# RL6842_IP_SVD register map
Vendor: Realtek
Registers are 32-bit, read-write, reset 0x0 unless marked. A register's access mark holds for its fields unless they carry their own. Offsets are from the block's base; [hi:lo] are bit positions; {n}, {i} and the like mark numbered series.

## page1 (part 1 of 2)
Base 0x40000000
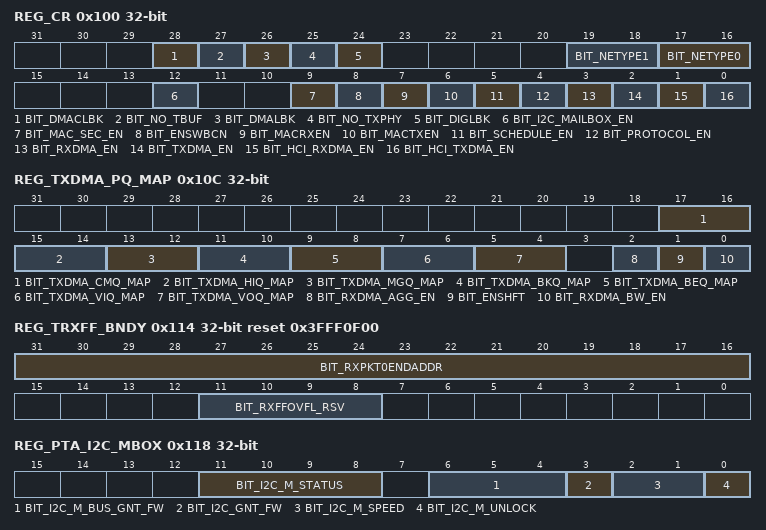
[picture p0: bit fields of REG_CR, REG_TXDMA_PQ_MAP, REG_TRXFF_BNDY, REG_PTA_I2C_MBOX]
0x100 REG_CR — MAC TOP Function enable
  [28] BIT_DMACLBK — [28:24] LBMODE [4]dual-mac lbk, [3] no buffer, 1: no delay, 0: delay; [2] dmalbk, [1] no_txphy, [0] diglbk. 00000: Normal 01011: Single MAC Direct loopback (no HW encryption/decryption) 00011: Single MAC Delay Loopback (with HW encryption/decryption)
  [27] BIT_NO_TBUF
  [26] BIT_DMALBK
  [25] BIT_NO_TXPHY
  [24] BIT_DIGLBK
  [19:18] BIT_NETYPE1 — Network Type for Port 1 00: No link 01: Link in ad hoc network 10: Link in infrastructure network 11 : AP mode Default: 00b.
  [17:16] BIT_NETYPE0 — Network Type for port 0 00: No link 01: Link in ad hoc network 10: Link in infrastructure network 11 : AP mode Default: 00b.
  [12] BIT_I2C_MAILBOX_EN — Enable I2C mailbox
  [9] BIT_MAC_SEC_EN — Enable MAC security engine When this bit is clear, security engine is reset
  [8] BIT_ENSWBCN — Enable SW TX beacon 0 : disable, beacon is DMAed from host memory by HW at BCNDMAINT 1 : enable, beacon is polled to DMA to TXBUF. In both case, as long as a beacon frame is set in BCN page, MAC will automatically sent beacon frame automatically.
  [7] BIT_MACRXEN — MAC Receiver Enable. When set to 1, and the receive state machine is idle, the receive machine becomes active. This bit will read back as 1 whenever the receive state machine is active. After initial power-up, software must ensure that the receiver has completely reset before setting this bit. 1: Enable 0: Disable Default: 0b.
  [6] BIT_MACTXEN — MAC Transmitter Enable. When set to 1, and the transmit state machine is idle, the transmit state machine becomes active. This bit will read back as 1 whenever the transmit state machine is active. After initial power-up, software must ensure that the transmitter has completely reset before setting this bit. 1: Enable 0: Disable Default: 0b.
  [5] BIT_SCHEDULE_EN — Schedule Enable.
  [4] BIT_PROTOCOL_EN — protocol Block Function Enable.(FW2HW)
  [3] BIT_RXDMA_EN — RXDMA Function Enable
  [2] BIT_TXDMA_EN — TXDMA Function Enable
  [1] BIT_HCI_RXDMA_EN — HCI to RXDMA Interface Enable
  [0] BIT_HCI_TXDMA_EN — HCI to TXDMA Interface Enable
0x104 REG_PG_SIZE
0x108 REG_TSF_CLK_STATE ro — Beacon time reset value
  [15] BIT_CLK_TSF_IS32K — Which Clock is Used by TSF Clock 1: 32K Clock 0: MAC Clock
0x10C REG_TXDMA_PQ_MAP — RX DMA Fuction enable
  [17:16] BIT_TXDMA_CMQ_MAP — 00: Extra priority queue 01: Low priority queue 10: Normal priority queue 11: High priority queue
  [15:14] BIT_TXDMA_HIQ_MAP — 00: Extra priority queue 01: Low priority queue 10: Normal priority queue 11: High priority queue
  [13:12] BIT_TXDMA_MGQ_MAP — 00: Extra priority queue 01: Low priority queue 10: Normal priority queue 11: High priority queue
  [11:10] BIT_TXDMA_BKQ_MAP — 00: Extra priority queue 01: Low priority queue 10: Normal priority queue 11: High priority queue
  [9:8] BIT_TXDMA_BEQ_MAP — 00: Extra priority queue 01: Low priority queue 10: Normal priority queue 11: High priority queue
  [7:6] BIT_TXDMA_VIQ_MAP — 00: Extra priority queue 01: Low priority queue 10: Normal priority queue 11: High priority queue
  [5:4] BIT_TXDMA_VOQ_MAP — 00: Extra priority queue 01: Low priority queue 10: Normal priority queue 11: High priority queue
  [2] BIT_RXDMA_AGG_EN — When this bit is set, then RXDMA will inform host to receive RX packets, when packet page number in RXFF exceeds the threshold set in RXDMA_AGG_PG_TH register. When this bit is set, then page size of receive packet buffer shall be set larger than 64 bytes/page
  [1] BIT_ENSHFT — When this bit is set, RX shift to fit alignment is enabled.
  [0] BIT_RXDMA_BW_EN — Enable RXDMA Arbitrator priority for Host interface.
0x114 REG_TRXFF_BNDY reset 0x3FFF0F00 — FIFO Boundary control register
  [31:16] BIT_RXPKT0ENDADDR — This register sets the upper boundary of RXFF0. The unit is 1 byte. The available memory space in RXPKTBUF for RXFF0 is configurable. The value is set to the physical LX bus address.
  [11:8] BIT_RXFFOVFL_RSV — Use this register to set reserved entries number of rxpktbuffer for overflow judgment. The rxpktbuffer overflow will be pre-asserted if the left entries count meets the value set here.
0x118 REG_PTA_I2C_MBOX access per field — Status register-FIFO status
  [11:8] BIT_I2C_M_STATUS ro — Read these can get the I2C_M_STATUS of PTA_I2C's OUTPUT.
  [6:4] BIT_I2C_M_BUS_GNT_FW rw — Use this bit to control PTA_I2C's BUS_GNT. 100 for gnt_txdata, 010 for gnt_txack, 001 for gnt_rxstatus.
  [3] BIT_I2C_GNT_FW rw — Use this bit to control PTA_I2C_GNT_FW input. 1 for FW I2C bus arbiter, 0 for HW as I2C bus arbiter.
  [2:1] BIT_I2C_M_SPEED rw — Use these bit to control PTA_I2C I2C interface data rate. SCL = clk / 2^(3 + I2C_DATA_RATE)
  [0] BIT_I2C_M_UNLOCK rw — If this bit is set, PTA_I2C use 118H and 119H to control PTA_I2C
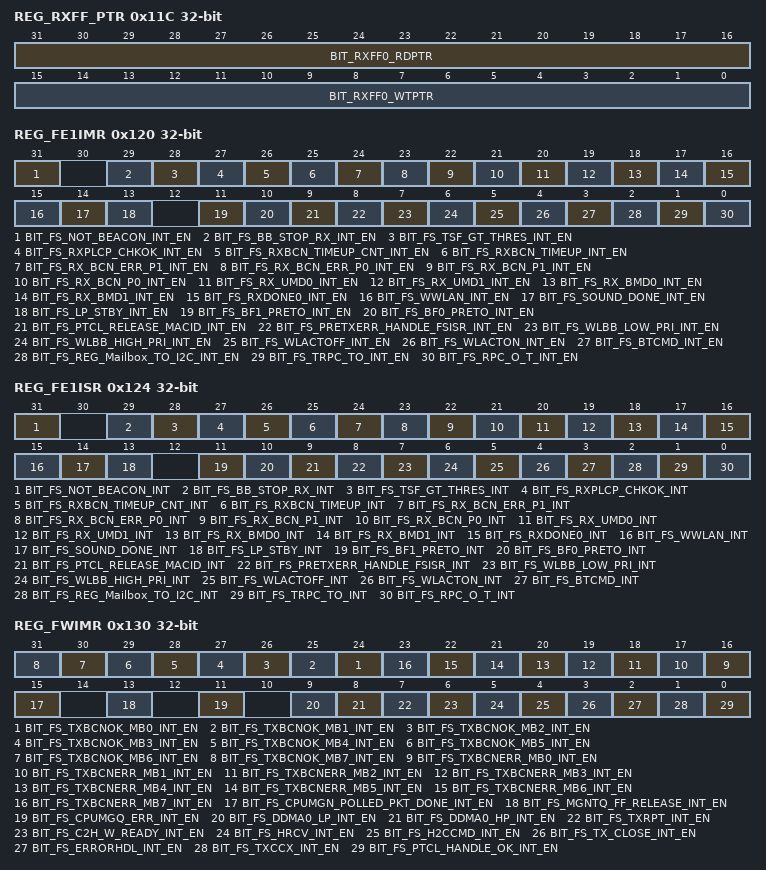
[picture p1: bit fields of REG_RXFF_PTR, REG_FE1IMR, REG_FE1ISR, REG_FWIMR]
0x11C REG_RXFF_PTR ro — RX FIFO Read/write pointer
  [31:16] BIT_RXFF0_RDPTR — The read pointer address of RXFF0. The value is set to the physical LX bus address.
  [15:0] BIT_RXFF0_WTPTR — The write pointer address of RXFF0. The value is set to the physical LX bus address.
0x120 REG_FE1IMR
  [31] BIT_FS_NOT_BEACON_INT_EN — not beacon packet interrupt
  [29] BIT_FS_BB_STOP_RX_INT_EN — BB STOP RX interrupt
  [28] BIT_FS_TSF_GT_THRES_INT_EN — The interrupt is issued when difference of tsft in beacon frame of port0 is greater than threshold
  [27] BIT_FS_RXPLCP_CHKOK_INT_EN — RXPCLP check ok interrupt
  [26] BIT_FS_RXBCN_TIMEUP_CNT_INT_EN — When this bit is enable, the interrupt is issued when RX beacon frame timeout occurs specified times in port0.specified by 0x17C[23:20]
  [25] BIT_FS_RXBCN_TIMEUP_INT_EN — When this bit is enable, the interrupt is issued when RX beacon frame timeout occurs in port0.
  [24] BIT_FS_RX_BCN_ERR_P1_INT_EN — When this bit is enable, the interrupt is issued when RX beacon frame with fcs error occurs in port1.
  [23] BIT_FS_RX_BCN_ERR_P0_INT_EN — When this bit is enable, the interrupt is issued when RX beacon frame with fcs error occurs in port0.
  [22] BIT_FS_RX_BCN_P1_INT_EN — When this bit is enable, the interrupt is issued when RX beacon frame occurs in port1.
  [21] BIT_FS_RX_BCN_P0_INT_EN — When this bit is enable, the interrupt is issued when RX beacon frame occurs in port0.
  [20] BIT_FS_RX_UMD0_INT_EN — The interrupt is issued while receiving unicast data frame with More Data=0
  [19] BIT_FS_RX_UMD1_INT_EN — The interrupt is issued while receiving unicast data frame with More Data=1
  [18] BIT_FS_RX_BMD0_INT_EN — The interrupt is issued while receiving broadcast data frame with More Data=0
  [17] BIT_FS_RX_BMD1_INT_EN — The interrupt is issued while receiving broadcast data frame with More Data=1
  [16] BIT_FS_RXDONE0_INT_EN — Rx Packet 0 done interrupt (for WOL release packet)
  [15] BIT_FS_WWLAN_INT_EN — HW detect rxpkt Wol WLAN event interrupt
  [14] BIT_FS_SOUND_DONE_INT_EN — Be a beamformer, this interrupt is issued at the time after sounding finish
  [13] BIT_FS_LP_STBY_INT_EN — Lower Power Standby Interrupt
  [11] BIT_FS_BF1_PRETO_INT_EN — BF1 pretimeout interrupt
  [10] BIT_FS_BF0_PRETO_INT_EN — BF0 pretimeout interrupt
  [9] BIT_FS_PTCL_RELEASE_MACID_INT_EN — PTCL release macid interrupt
  [8] BIT_FS_PRETXERR_HANDLE_FSISR_INT_EN — PRETXERR_HANDLE FW Flag Interrupt register.
  [7] BIT_FS_WLBB_LOW_PRI_INT_EN — ERROR happened in bb,not fatal
  [6] BIT_FS_WLBB_HIGH_PRI_INT_EN — fatal error happened in bb
  [5] BIT_FS_WLACTOFF_INT_EN — WL_ACT_MASK_ON de-assertion for bt coexistence function interrupt
  [4] BIT_FS_WLACTON_INT_EN — WL_ACT_MASK_ON assertion for bt coexistence function interrupt
  [3] BIT_FS_BTCMD_INT_EN — the interrupt is issued when btcmd occurs.
  [2] BIT_FS_REG_Mailbox_TO_I2C_INT_EN — Mailbox_TO_I2C_INT (BT bridge)
  [1] BIT_FS_TRPC_TO_INT_EN — TRPC time out Interrupt
  [0] BIT_FS_RPC_O_T_INT_EN — RPC over threshold Interrupt
0x124 REG_FE1ISR ro — Firmware Extend Interrupt Status Register
  [31] BIT_FS_NOT_BEACON_INT — not beacon packet interrupt
  [29] BIT_FS_BB_STOP_RX_INT — BB STOP RX interrupt
  [28] BIT_FS_TSF_GT_THRES_INT — The interrupt is issued when difference of tsft in beacon frame is greater than threshold
  [27] BIT_FS_RXPLCP_CHKOK_INT — RXPCLP check ok interrupt
  [26] BIT_FS_RXBCN_TIMEUP_CNT_INT — When this bit is enable, the interrupt is issued when RX beacon frame timeout occurs specified times in port0.specified by 0x17C[23:20]
  [25] BIT_FS_RXBCN_TIMEUP_INT — When this bit is enable, the interrupt is issued when RX beacon frame timeout occurs in port0.
  [24] BIT_FS_RX_BCN_ERR_P1_INT — When this bit is enable, the interrupt is issued when RX beacon frame with fcs error occurs in port1.
  [23] BIT_FS_RX_BCN_ERR_P0_INT — When this bit is enable, the interrupt is issued when RX beacon frame with fcs error occurs in port0.
  [22] BIT_FS_RX_BCN_P1_INT — When this bit is enable, the interrupt is issued when RX beacon frame occurs in port1.
  [21] BIT_FS_RX_BCN_P0_INT — When this bit is enable, the interrupt is issued when RX beacon frame occurs in port0.
  [20] BIT_FS_RX_UMD0_INT — The interrupt is issued while receiving unicast data frame with More Data=0
  [19] BIT_FS_RX_UMD1_INT — The interrupt is issued while receiving unicast data frame with More Data=1
  [18] BIT_FS_RX_BMD0_INT — The interrupt is issued while receiving broadcast data frame with More Data=0
  [17] BIT_FS_RX_BMD1_INT — The interrupt is issued while receiving broadcast data frame with More Data=1
  [16] BIT_FS_RXDONE0_INT — Rx Packet 0 done interrupt (for WOL release packet)
  [15] BIT_FS_WWLAN_INT — HW detect rxpkt Wol WLAN event interrupt
  [14] BIT_FS_SOUND_DONE_INT — Be a beamformer, this interrupt is issued at the time after sounding finish
  [13] BIT_FS_LP_STBY_INT — Lower Power Standby Interrupt
  [11] BIT_FS_BF1_PRETO_INT — BF1 pretimeout interrupt
  [10] BIT_FS_BF0_PRETO_INT — BF0 pretimeout interrupt
  [9] BIT_FS_PTCL_RELEASE_MACID_INT — PTCL release macid interrupt
  [8] BIT_FS_PRETXERR_HANDLE_FSISR_INT — PRETXERR_HANDLE FW Flag Interrupt register.
  [7] BIT_FS_WLBB_LOW_PRI_INT — ERROR happened in bb,not fatal
  [6] BIT_FS_WLBB_HIGH_PRI_INT — fatal error happened in bb
  [5] BIT_FS_WLACTOFF_INT — WL_ACT_MASK_ON de-assertion for bt coexistence function interrupt
  [4] BIT_FS_WLACTON_INT — WL_ACT_MASK_ON assertion for bt coexistence function interrupt
  [3] BIT_FS_BTCMD_INT — the interrupt is issued when btcmd occurs.
  [2] BIT_FS_REG_Mailbox_TO_I2C_INT — Mailbox_TO_I2C_INT (BT bridge)
  [1] BIT_FS_TRPC_TO_INT — tx/rx pkt time out Interrupt
  [0] BIT_FS_RPC_O_T_INT — RXPKT counter over threshold Interrupt
0x130 REG_FWIMR — Firmware Interrupt Mask Register
  [n+24] BIT_FS_TXBCNOK_MB{n}_INT_EN (n=0..7) — MBSSID{n} TX beacon OK interrupt
  [n+16] BIT_FS_TXBCNERR_MB{n}_INT_EN (n=0..7) — MBSSID{n} TX beacon Error interrupt
  [15] BIT_FS_CPUMGN_POLLED_PKT_DONE_INT_EN — CPU management queue polled packet released done interrupt enable (check cpu management queue current flow)
  [13] BIT_FS_MGNTQ_FF_RELEASE_INT_EN — MgntQ ReadPtr FIFO release interrupt (for 8822B)
  [11] BIT_FS_CPUMGQ_ERR_INT_EN — CPU management queue polled packet not TX OK while new packet comes in, enable to issue interrupt or not
  [9] BIT_FS_DDMA0_LP_INT_EN — Low priority ddma0 down interrupt .
  [8] BIT_FS_DDMA0_HP_INT_EN — High priority ddma0 down interrupt
  [7] BIT_FS_TXRPT_INT_EN — TX report interrupt
  [6] BIT_FS_C2H_W_READY_INT_EN — C2H register ready for write interrupt
  [5] BIT_FS_HRCV_INT_EN — Host to CPU Message Interrupt, generated on writing to 0x1CF
  [4] BIT_FS_H2CCMD_INT_EN — Host To CPU Message Interrupt
  [3] BIT_FS_TX_CLOSE_INT_EN — TX DONE INTERRUPT
  [2] BIT_FS_ERRORHDL_INT_EN — FWHW/ TXDMA/ RXDMA/ WMAC error status interrupt(0x210[31:0], 0x288[31:0], 0x4E2[15:0], 0x6B8[31:0]). WMAC error state will be recovered by HW, the others won't.
  [1] BIT_FS_TXCCX_INT_EN — CCX PKT TX Report Interrupt
  [0] BIT_FS_PTCL_HANDLE_OK_INT_EN — TX Finish (Ack/BA process Finish) Interrupt.
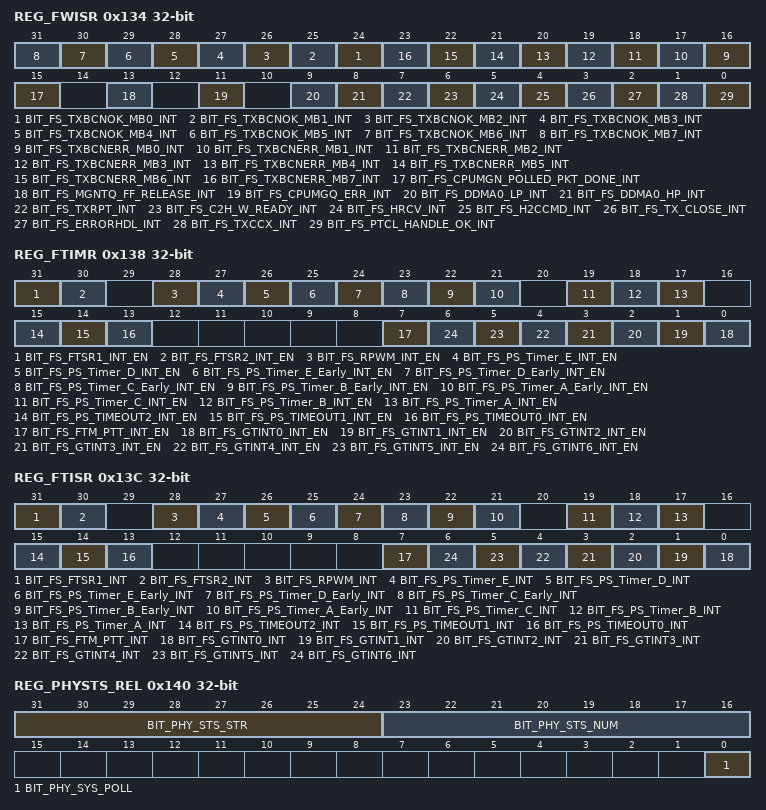
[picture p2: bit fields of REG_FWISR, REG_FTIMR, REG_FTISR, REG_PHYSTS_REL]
0x134 REG_FWISR ro — Firmware Interrupt Status Register
  [n+24] BIT_FS_TXBCNOK_MB{n}_INT (n=0..7) — MBSSID{n} TX beacon OK interrupt
  [n+16] BIT_FS_TXBCNERR_MB{n}_INT (n=0..7) — MBSSID{n} TX beacon Error interrupt
  [15] BIT_FS_CPUMGN_POLLED_PKT_DONE_INT — CPU management queue polled packet released done interrupt enable (check cpu management queue current flow)
  [13] BIT_FS_MGNTQ_FF_RELEASE_INT — MgntQ ReadPtr FIFO release interrupt (for 8822B)
  [11] BIT_FS_CPUMGQ_ERR_INT — CPU management queue polled packet not TX OK while new packet comes in, enable to issue interrupt or not
  [9] BIT_FS_DDMA0_LP_INT — Low priority ddma0 down interrupt .
  [8] BIT_FS_DDMA0_HP_INT — High priority ddma0 down interrupt
  [7] BIT_FS_TXRPT_INT — TX report interrupt
  [6] BIT_FS_C2H_W_READY_INT — C2H register ready for write interrupt
  [5] BIT_FS_HRCV_INT — Host to CPU Message Interrupt, generated on writing to 0x1CF
  [4] BIT_FS_H2CCMD_INT — Host To CPU Message Interrupt
  [3] BIT_FS_TX_CLOSE_INT — TX DONE INTERRUPT
  [2] BIT_FS_ERRORHDL_INT — FWHW/ TXDMA/ RXDMA/ WMAC error status interrupt(0x210[31:0], 0x288[31:0], 0x4E2[15:0], 0x6B8[31:0]). WMAC error state will be recovered by HW, the others won't.
  [1] BIT_FS_TXCCX_INT — CCX PKT TX Report Interrupt
  [0] BIT_FS_PTCL_HANDLE_OK_INT — TX Finish (Ack/BA process Finish) Interrupt.
0x138 REG_FTIMR — Firmware Timer Interrupt Mask Register
  [31] BIT_FS_FTSR1_INT_EN — FTMR1 Indicator (FTMR1 and FTMR1 are true, this bit is set to 1)
  [30] BIT_FS_FTSR2_INT_EN — FTMR2 Indicator (FTMR2 and FTMR2 are true, this bit is set to 1)
  [28] BIT_FS_RPWM_INT_EN — RPWM interrupt
  [27] BIT_FS_PS_Timer_E_INT_EN — PS_Timer_E interrupt When the TSF(that select by reg 0x1520[13:12]) matches the content of this register, the PS_Timer_E_INT interrupt is issued
  [26] BIT_FS_PS_Timer_D_INT_EN — PS_Timer_D interrupt When the lower 4 bytes of TSF(that select by reg 0x1520[17:16]) matches the content of this register, the PS_Timer_D_INT interrupt is issued
  [25] BIT_FS_PS_Timer_E_Early_INT_EN — This interrupt is issued at the time set by PS_Timer_E_Early register before PS_Timer_E time.
  [24] BIT_FS_PS_Timer_D_Early_INT_EN — This interrupt is issued at the time set by PS_Timer_D_Early register before PS_Timer_D time.
  [23] BIT_FS_PS_Timer_C_Early_INT_EN — This interrupt is issued at the time set by PS_Timer_C_Early register before PS_Timer_C time.
  [22] BIT_FS_PS_Timer_B_Early_INT_EN — This interrupt is issued at the time set by PS_Timer_B_Early register before PS_Timer_B time.
  [21] BIT_FS_PS_Timer_A_Early_INT_EN — This interrupt is issued at the time set by PS_Timer_A_Early register before PS_Timer_A time.
  [19] BIT_FS_PS_Timer_C_INT_EN — PS_Timer_C interrupt When the lower 4 bytes of TSF(that select by reg 0x1510[18:16]) matches the content of this register, the PS_Timer_C_INT interrupt is issued
  [18] BIT_FS_PS_Timer_B_INT_EN — PS_Timer_B interrupt When the lower 4 bytes of TSF(that select by reg 0x1510[10:8]) matches the content of this register, the PS_Timer_B_INT interrupt is issued
  [17] BIT_FS_PS_Timer_A_INT_EN — PS_Timer_A interrupt When the lower 4 bytes of TSF(that select by reg 0x1510[2:0]) matches the content of this register, the PS_Timer_A_INT interrupt is issued
  [15] BIT_FS_PS_TIMEOUT2_INT_EN — PS_TimeOut2 interrupt . When the lower 4 bytes of FREERUN CNT matches the content of this register(0x588), the FW PS_TimeOut2 interrupt is issued.
  [14] BIT_FS_PS_TIMEOUT1_INT_EN — PS_TimeOut1 interrupt . When the lower 4 bytes of TSFTR(that select by 0x5b1[5:3]) matches the content of this register(0x584), the FW PS_TimeOut1 interrupt is issued.
  [13] BIT_FS_PS_TIMEOUT0_INT_EN — PS_TimeOut0 interrupt . When the lower 4 bytes of TSFTR(that select by 0x5b4[2:0]) matches the content of this register(0x580), the FW PS_TimeOut0 interrupt is issued.
  [7] BIT_FS_FTM_PTT_INT_EN — Partial tsf timer
  [n] BIT_FS_GTINT{n}_INT_EN (n=0..6) — General Timer[{n}] interrupt
0x13C REG_FTISR ro — Firmware Timer Interrupt Status Register
  [31] BIT_FS_FTSR1_INT — FTMR1 Indicator (FTMR1 and FTMR1 are true, this bit is set to 1)
  [30] BIT_FS_FTSR2_INT — FTMR2 Indicator (FTMR2 and FTMR2 are true, this bit is set to 1)
  [28] BIT_FS_RPWM_INT — RPWM interrupt
  [27] BIT_FS_PS_Timer_E_INT — PS_Timer_E interrupt When the TSF(that select by reg 0x1520[13:12]) matches the content of this register, the PS_Timer_E_INT interrupt is issued
  [26] BIT_FS_PS_Timer_D_INT — PS_Timer_D interrupt When the lower 4 bytes of TSF(that select by reg 0x1520[17:16]) matches the content of this register, the PS_Timer_D_INT interrupt is issued
  [25] BIT_FS_PS_Timer_E_Early_INT — This interrupt is issued at the time set by PS_Timer_E_Early register before PS_Timer_E time.
  [24] BIT_FS_PS_Timer_D_Early_INT — This interrupt is issued at the time set by PS_Timer_D_Early register before PS_Timer_D time.
  [23] BIT_FS_PS_Timer_C_Early_INT — This interrupt is issued at the time set by PS_Timer_C_Early register before PS_Timer_C time.
  [22] BIT_FS_PS_Timer_B_Early_INT — This interrupt is issued at the time set by PS_Timer_B_Early register before PS_Timer_B time.
  [21] BIT_FS_PS_Timer_A_Early_INT — This interrupt is issued at the time set by PS_Timer_A_Early register before PS_Timer_A time.
  [19] BIT_FS_PS_Timer_C_INT — PS_Timer_C interrupt When the lower 4 bytes of TSF(that select by reg 0x1510[18:16]) matches the content of this register, the PS_Timer_C_INT interrupt is issued
  [18] BIT_FS_PS_Timer_B_INT — PS_Timer_B interrupt When the lower 4 bytes of TSF(that select by reg 0x1510[10:8]) matches the content of this register, the PS_Timer_B_INT interrupt is issued
  [17] BIT_FS_PS_Timer_A_INT — PS_Timer_A interrupt When the lower 4 bytes of TSF(that select by reg 0x1510[2:0]) matches the content of this register, the PS_Timer_A_INT interrupt is issued
  [15] BIT_FS_PS_TIMEOUT2_INT — PS_TimeOut2 interrupt . When the lower 4 bytes of FREERUN CNT matches the content of this register(0x588), the FW PS_TimeOut2 interrupt is issued.
  [14] BIT_FS_PS_TIMEOUT1_INT — PS_TimeOut1 interrupt . When the lower 4 bytes of TSFTR(that select by 0x5b1[5:3]) matches the content of this register(0x584), the FW PS_TimeOut1 interrupt is issued.
  [13] BIT_FS_PS_TIMEOUT0_INT — PS_TimeOut0 interrupt . When the lower 4 bytes of TSFTR(that select by 0x5b4[2:0]) matches the content of this register(0x580), the FW PS_TimeOut0 interrupt is issued.
  [7] BIT_FS_FTM_PTT_INT — Partial tsf timer
  [n] BIT_FS_GTINT{n}_INT (n=0..6) — General Timer[{n}] interrupt
0x140 REG_PHYSTS_REL — PHYSTS REALSE
  [31:24] BIT_PHY_STS_STR — physts start read address,8 bytes unit
  [23:16] BIT_PHY_STS_NUM — physts packet number in physts buffer
  [0] BIT_PHY_SYS_POLL — physts release polling,when polling done,write the bit to 0
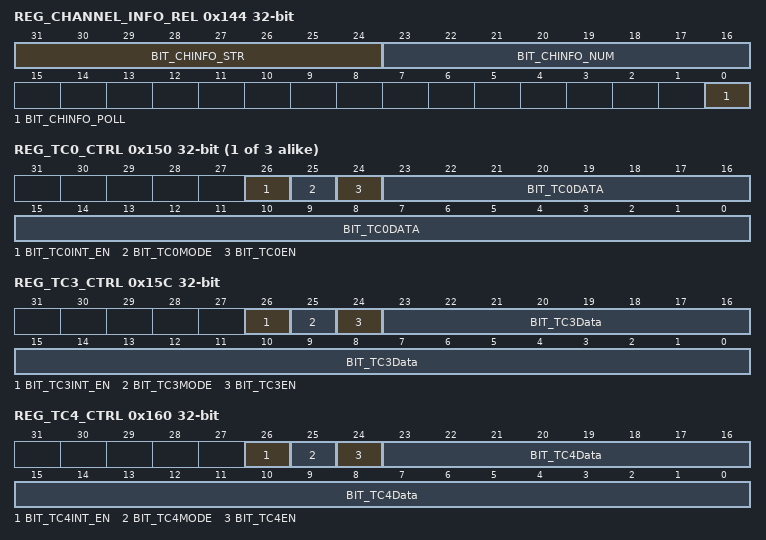
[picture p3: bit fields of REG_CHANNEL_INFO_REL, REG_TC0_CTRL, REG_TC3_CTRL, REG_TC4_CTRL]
0x144 REG_CHANNEL_INFO_REL — CHANNEL INFO REALSE
  [31:24] BIT_CHINFO_STR — channel info start read address,8 bytes unit
  [23:16] BIT_CHINFO_NUM — channel info packet number in csi buffer
  [0] BIT_CHINFO_POLL — channel info release polling,when polling done,write the bit to 0
{0x150+4i} REG_TC{i}_CTRL (i=0..2) — Counter {i} data
  [26] BIT_TC{i}INT_EN — When write "1" to this bit, Counter {i} starts counting down. This is a one-bit pulse.
  [25] BIT_TC{i}MODE — Timer/Counter {i} mode 0=counter mode 1=timer mode
  [24] BIT_TC{i}EN — Timer/Counter {i} enable
  [23:0] BIT_TC{i}DATA — Timer/Counter {i} data register. It specifies the time-out duration.
0x15C REG_TC3_CTRL — Counter 3 data
  [26] BIT_TC3INT_EN — When write "1" to this bit, Counter 3 starts counting down. This is a one-bit pulse.
  [25] BIT_TC3MODE — Timer/Counter 3 mode 0=counter mode 1=timer mode
  [24] BIT_TC3EN — Timer/Counter 3 enable
  [23:0] BIT_TC3Data — Timer/Counter 3 data register. It specifies the time-out duration.
0x160 REG_TC4_CTRL — Counter 4 data
  [26] BIT_TC4INT_EN — When write "1" to this bit, Counter 4 starts counting down. This is a one-bit pulse.
  [25] BIT_TC4MODE — Timer/Counter 4mode 0=counter mode 1=timer mode
  [24] BIT_TC4EN — Timer/Counter 4 enable
  [23:0] BIT_TC4Data — Timer/Counter 4 data register. It specifies the time-out duration.
0x164 REG_TCUNIT_BASE — Control Register
  [13:0] BIT_TC_UNIT_BASE — The register set the number of clocks that equals to the base time unit of timer/counter. The clock domain is 32k clock domain.
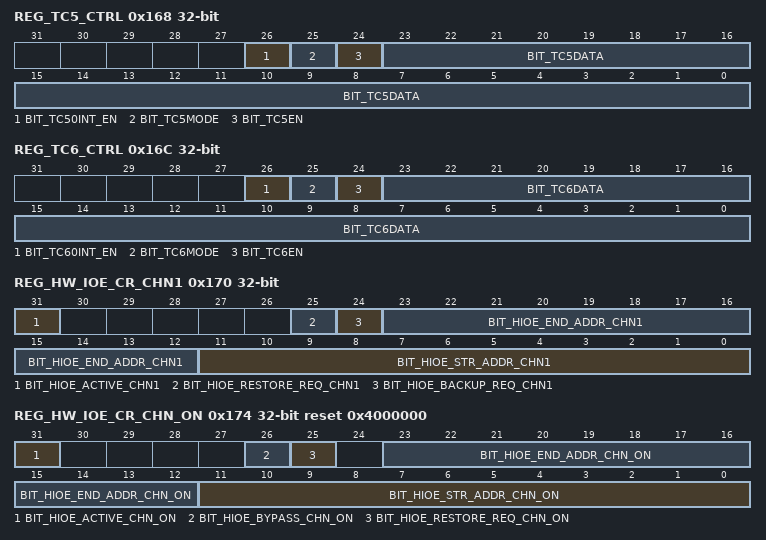
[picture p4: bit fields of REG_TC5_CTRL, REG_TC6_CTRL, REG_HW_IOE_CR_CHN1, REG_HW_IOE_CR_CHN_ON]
0x168 REG_TC5_CTRL — Counter 5 data
  [26] BIT_TC50INT_EN — When write "1" to this bit, Counter 5 starts counting down. This is a one-bit pulse.
  [25] BIT_TC5MODE — Timer/Counter 5 mode 0=counter mode 1=timer mode
  [24] BIT_TC5EN — Timer/Counter5 enable
  [23:0] BIT_TC5DATA — Timer/Counter 5 data register. It specifies the time-out duration.
0x16C REG_TC6_CTRL — Counter 6 data
  [26] BIT_TC60INT_EN — When write "1" to this bit, Counter 6 starts counting down. This is a one-bit pulse.
  [25] BIT_TC6MODE — Timer/Counter 6 mode 0=counter mode 1=timer mode
  [24] BIT_TC6EN — Timer/Counter6 enable
  [23:0] BIT_TC6DATA — Timer/Counter 6 data register. It specifies the time-out duration.
0x170 REG_HW_IOE_CR_CHN1 access per field — HW IO Engine Configure Register_CHN1
  [31] BIT_HIOE_ACTIVE_CHN1 ro — indicate HIOE engine is active
  [25] BIT_HIOE_RESTORE_REQ_CHN1 rw — WLOFF REG restore request, clear by hw
  [24] BIT_HIOE_BACKUP_REQ_CHN1 rw — WLOFF REG backup request, clear by hw
  [23:12] BIT_HIOE_END_ADDR_CHN1 rw — HIOE command end address in txpktbuffer, unit:8byte
  [11:0] BIT_HIOE_STR_ADDR_CHN1 rw — HIOE command start address in txpktbuffer, unit:8byte
0x174 REG_HW_IOE_CR_CHN_ON access per field reset 0x4000000 — HW IO Engine Configure Register_CHN_ON
  [31] BIT_HIOE_ACTIVE_CHN_ON ro — indicate HIOE engine is active, used for wlan power on flow
  [26] BIT_HIOE_BYPASS_CHN_ON rw — BYPASS HW trig hioe to do rf on flow
  [25] BIT_HIOE_RESTORE_REQ_CHN_ON ro — WLOFF REG restore request, clear by hw
  [23:12] BIT_HIOE_END_ADDR_CHN_ON rw — HIOE command end address in txpktbuffer, unit:8byte
  [11:0] BIT_HIOE_STR_ADDR_CHN_ON rw — HIOE command start address in txpktbuffer, unit:8byte
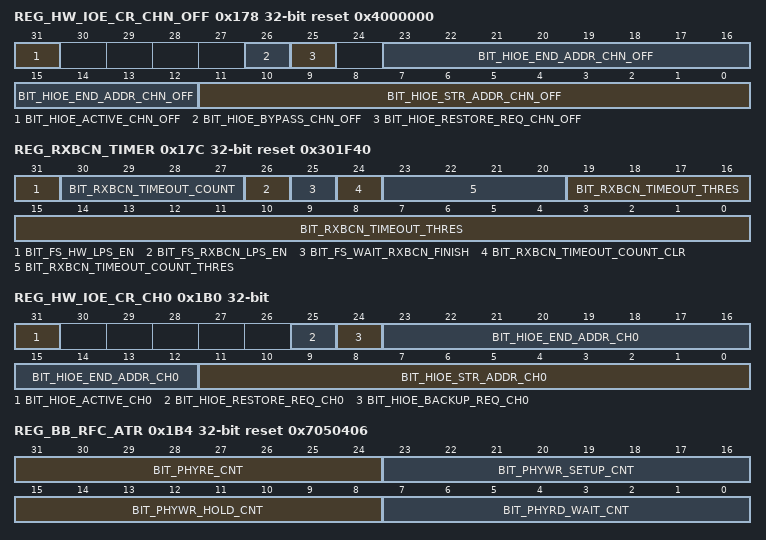
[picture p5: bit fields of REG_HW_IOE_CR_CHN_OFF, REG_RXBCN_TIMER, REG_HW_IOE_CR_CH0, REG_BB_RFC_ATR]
0x178 REG_HW_IOE_CR_CHN_OFF access per field reset 0x4000000 — HW IO Engine Configure Register_CHN_OFF
  [31] BIT_HIOE_ACTIVE_CHN_OFF ro — indicate HIOE engine is active, used for wlan power off flow
  [26] BIT_HIOE_BYPASS_CHN_OFF rw — BYPASS HW trig hioe to do rf off flow
  [25] BIT_HIOE_RESTORE_REQ_CHN_OFF ro — WLOFF REG restore request, clear by hw
  [23:12] BIT_HIOE_END_ADDR_CHN_OFF rw — HIOE command end address in txpktbuffer, unit:8byte
  [11:0] BIT_HIOE_STR_ADDR_CHN_OFF rw — HIOE command start address in txpktbuffer, unit:8byte
0x17C REG_RXBCN_TIMER access per field reset 0x301F40
  [31] BIT_FS_HW_LPS_EN rw — enable HW enter lps after hioe_off_int rise when BIT_FS_RXBCN_LPS_EN=1
  [30:27] BIT_RXBCN_TIMEOUT_COUNT ro — rxbcn timeout counter
  [26] BIT_FS_RXBCN_LPS_EN rw — enable lps offload flow when rxbcn frame in port0 acting as a non-AP STA.
  [25] BIT_FS_WAIT_RXBCN_FINISH rw — when rxbcn frame, turn off rf or generate interrupt ablout rxbcn after beacon fcs is parsered
  [24] BIT_RXBCN_TIMEOUT_COUNT_CLR rw — clear rxbcn timeout counter
  [23:20] BIT_RXBCN_TIMEOUT_COUNT_THRES rw — threshold for rxbcn timeout counter,when 0x17C[30:27] equals to this value,generate interrupt
  [19:0] BIT_RXBCN_TIMEOUT_THRES rw — threshold for rxbcn timeout,UNIT:us default:8ms
0x1B0 REG_HW_IOE_CR_CH0 access per field — HW IO Engine Configure Register_CH0
  [31] BIT_HIOE_ACTIVE_CH0 ro — indicate HIOE engine is active
  [25] BIT_HIOE_RESTORE_REQ_CH0 rw — WLOFF REG restore request, clear by hw
  [24] BIT_HIOE_BACKUP_REQ_CH0 rw — WLOFF REG backup request, clear by hw
  [23:12] BIT_HIOE_END_ADDR_CH0 rw — HIOE command end address in txpktbuffer, unit:8byte
  [11:0] BIT_HIOE_STR_ADDR_CH0 rw — HIOE command start address in txpktbuffer, unit:8byte
0x1B4 REG_BB_RFC_ATR reset 0x7050406 — BB/RFC REG Access Time Register
  [31:24] BIT_PHYRE_CNT — the timing after RE for host/cpu access BB/RFC REG
  [23:16] BIT_PHYWR_SETUP_CNT — the timing WDATA stable before WE for host/cpu access BB/RFC REG
  [15:8] BIT_PHYWR_HOLD_CNT — the timing WDATA stable after WE for host/cpu access BB/RFC REG
  [7:0] BIT_PHYRD_WAIT_CNT — the timing RDATA stable after ADDR for host/cpu access BB/RFC REG
0x1B8 REG_FW_DBG12 — SD Reserved register for FW debug
  [31:0] BIT_SW_DEFINED_PAGE1_V1 — User Defined Message
0x1BC REG_FW_DBG13 — SD Reserved register for FW debug
  [31:0] BIT_SW_DEFINED_PAGE2 — User Defined Message
0x1C0 REG_FW_DBG14 — SD Reserved register for FW debug
  [31:0] BIT_MCUDMSG_I — User Defined Message
0x1C4 REG_FW_DBG15 — SD Reserved register for FW debug
  [31:0] BIT_MCUDMSG_II — User Defined Message
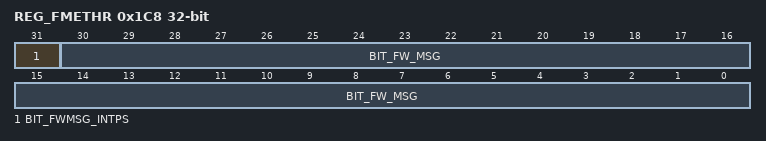
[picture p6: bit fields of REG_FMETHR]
0x1C8 REG_FMETHR — Firmware Message Mail Box Register
  [31] BIT_FWMSG_INTPS — Toggle this bit will generate C2H interrupt to Host
  [30:0] BIT_FW_MSG — User Defined Message
